# NAVSS0_BCDMA_0_ALIAS64K_BCDMA0_CFG_TCHAN register map
Vendor: Texas Instruments
Peripheral module from a debugger description file (folder J721S2).
Registers are 32-bit, read-write, reset 0x0 unless marked. A register's access mark holds for its fields unless they carry their own. Offsets are as the file gives them; lines under a group give offsets from that group; [hi:lo] are bit positions; {n}, {i} and the like mark numbered series; 'fields as' and 'values as' point back to an identical list; <NAME> marks a mode.

## NAVSS0_BCDMA_0_ALIAS64K_BCDMA0_CFG_TCHAN
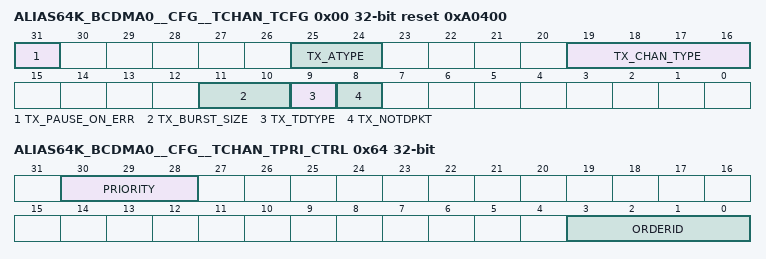
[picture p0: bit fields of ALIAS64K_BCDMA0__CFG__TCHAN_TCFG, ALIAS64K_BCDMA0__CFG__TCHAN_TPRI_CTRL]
0x00 ALIAS64K_BCDMA0__CFG__TCHAN_TCFG access not given reset 0xA0400 — The Tx Channel Configuration Register is used to initialize static mode settings for the Tx DMA channel. This register may only be written when the channel is disabled (tx_enable in realtime control reg is 0).
  [31] TX_PAUSE_ON_ERR rw — Pause On Error: this field controls what the channel will do if an error or exception occurs during a data transfer. This field is encoded as follows: 0 = Channel will drop current work and move on 1 = Channel will pause and wait for SW to investigate and un-pause the channel.
  [25:24] TX_ATYPE rw — This field controls how pointers will be interpreted for non Ring Accelerator accesses on this channel. The values are encoded as follows: 0 = Pointers are physical addresses 1 = Pointers are intermediate addresses which require intermediate to physical transaction before they can be decoded 2 = Pointers are virtual addresses which require virtual to physical translation before they can be decoded. All transactions from this channel which are not destined to the Ring Accelerator will have the mem*_catype attribute set equal to the value given in this register field. Accesses to the RA or descriptors will use the virtual credentials register.
  [19:16] TX_CHAN_TYPE — Channel Type: this field controls and / or indicates the functional channel type for this channel and the work passing mechanism that the channel uses for communicating with the Host. Available channel types are as follows: 0-9 = RESERVED 10 = Channel performs Third Party Block Copy DMA transfers from memory to PSI-L using pass by reference rings. 11-15 = RESERVED (access R/NA)
  [11:10] TX_BURST_SIZE rw — Specifies the nominal burst size and alignment for data transfers on this channel. 0 = 32 Bytes 1 = 64 Bytes 2 = 128 Bytes 3 = 256 bytes The optimal burst size setting is 256 Bytes to maximize utilization of the channel FIFOs.
  [9] TX_TDTYPE rw — Specifies whether or not the channel should immediately return a teardown completion response to the default completion queue or wait until a status message is returned from the remote PSI-L paired peripheral. 0 = return immediately once all traffic is complete in BCDMA. 1 = wait until remote peer sends back a completion message.
  [8] TX_NOTDPKT rw — Specifies whether or not the channel should suppress sending the single data phase teardown packet when teardown is complete. 0 = TD packet is sent 1 = Suppress sending TD packet
0x64 ALIAS64K_BCDMA0__CFG__TCHAN_TPRI_CTRL — The priority control register is used to control the priority of the transactions which the DMA generates on it's master interface.
  [30:28] PRIORITY — Tx Priority: This field contains the 3-bit value which will be output on the mem*_cpriority and mem_cepriority outputs during all transactions for this channel.
  [3:0] ORDERID — Tx Order ID: This field contains the 4-bit value which will be output on the mem*_corderid output during all transactions for this channel.
0x68 ALIAS64K_BCDMA0__CFG__TCHAN_TTHRD_ID — The thread ID mapping register is used to pair the Tx DMA channel to a specific destination thread. All traffic generated from this channel will be sent with a thread_id on the PSI-L interface with the value from this register.
  [15:0] THREAD_ID — Thread ID: This field contains the (up-to) 16-bit value which will be output on the strm_o_thread_id output during all transactions for this channel.
0x6C ALIAS64K_BCDMA0__CFG__TCHAN_TVIRT_CTRL — The Virtual ID register is used to set the virtual id to use for any transaction that uses non-Physical addresses.
  [11:0] VIRTID
0x70 ALIAS64K_BCDMA0__CFG__TCHAN_TFIFO_DEPTH reset 0x200 — The fifo depth register is used to specify how many FIFO data phases deep the Tx per channel FIFO will be for the channel. While the maximum depth of the Tx FIFO is set at design time, the FIFO depth can be artificially reduced in order to control the maximum latency which can be introduced due to buffering effects.
  [9:0] FDEPTH — FIFO Depth: This field contains the number of Tx FIFO bytes which will be allowed to be stored for the channel. The minimum value is equal to the PSI-L interface data path width (tstrm_wdth), the maximum value varies by channel class (ultra-high capacity/high capacity/normal capacity) and is equal to the tubuf_size/thbuf_size/tbuf_size parameter respectively multiplied by the PSI-L data path width (tstrm_wdth). The fdepth must always be an integer multiple of tstrm_wdth. The reset value of this register varies by channel class (ultra-high capacity/high capacity/normal capacity) but will be equal to the tubuf_size/thbuf_size/tbuf_size parameter respectively multiplied by the PSI-L interface data width (tstrm_wdth).
0x80 ALIAS64K_BCDMA0__CFG__TCHAN_TST_SCHED — The Tx Channel N Static Scheduler Configuration Register contains static configuration information which affects the conditions under which each channel will be given an opportunity to use the Tx DMA unit(s). The fields in this register are as follows:
  [1:0] PRIORITY — Tx Scheduling Priority: These bits select which scheduling bin the channel will be placed in for bandwidth allocation of the Tx DMA units. This field is encoded as follows: 0 = High priority 1 = Medium - high priority 2 = Medium - low priority 3 = Low priority Arbitration between bins is performed in a strict priority fashion. High priority channels will always be serviced first. If no high priority channels are requesting then all medium-high priority channels will be serviced next. If no high priority or medium-high priority channels are requesting then all medium-low priority channels will be serviced next. When no other channels are requesting, the low priority channels will be serviced. All channels within a given bin are serviced in a round robin order. Only channels which are enabled and which have sufficient free space in their Per Channel FIFO will be included in the round robin arbitration.
